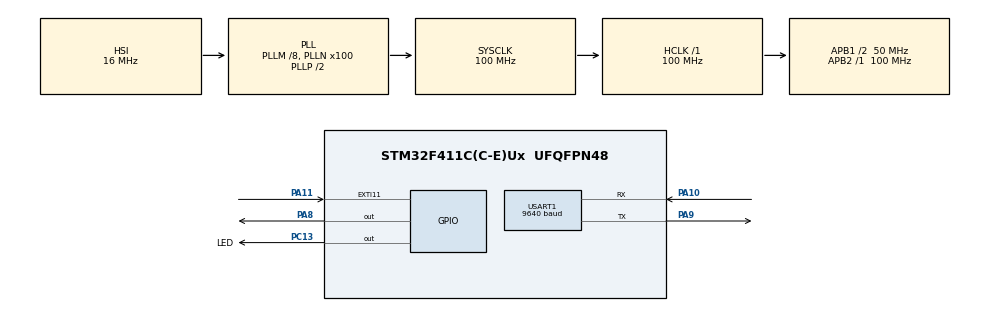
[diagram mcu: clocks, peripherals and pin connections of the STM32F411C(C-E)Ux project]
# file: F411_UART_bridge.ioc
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Dma.Request0=USART1_TX
Dma.Request1=USART1_RX
Dma.USART1_RX.1.Direction=DMA_PERIPH_TO_MEMORY
Dma.USART1_RX.1.FIFOMode=DMA_FIFOMODE_DISABLE
Dma.USART1_RX.1.Instance=DMA2_Stream2
Dma.USART1_RX.1.MemDataAlignment=DMA_MDATAALIGN_BYTE
Dma.USART1_RX.1.MemInc=DMA_MINC_ENABLE
Dma.USART1_RX.1.Mode=DMA_CIRCULAR
Dma.USART1_RX.1.PeriphDataAlignment=DMA_PDATAALIGN_BYTE
Dma.USART1_RX.1.PeriphInc=DMA_PINC_DISABLE
Dma.USART1_RX.1.Priority=DMA_PRIORITY_LOW
Dma.USART1_TX.0.Direction=DMA_MEMORY_TO_PERIPH
Dma.USART1_TX.0.FIFOMode=DMA_FIFOMODE_DISABLE
Dma.USART1_TX.0.Instance=DMA2_Stream7
Dma.USART1_TX.0.MemDataAlignment=DMA_MDATAALIGN_BYTE
Dma.USART1_TX.0.MemInc=DMA_MINC_ENABLE
Dma.USART1_TX.0.Mode=DMA_NORMAL
Dma.USART1_TX.0.PeriphDataAlignment=DMA_PDATAALIGN_BYTE
Dma.USART1_TX.0.PeriphInc=DMA_PINC_DISABLE
Dma.USART1_TX.0.Priority=DMA_PRIORITY_LOW
Mcu.Family=STM32F4
Mcu.Name=STM32F411C(C-E)Ux
Mcu.Package=UFQFPN48
NVIC.DMA2_Stream2_IRQn=true\:0\:0\:true\:false\:true\:false\:true\:true
NVIC.DMA2_Stream7_IRQn=true\:0\:0\:false\:false\:true\:false\:true\:true
NVIC.EXTI15_10_IRQn=true\:1\:0\:true\:false\:true\:true\:true\:true
NVIC.PriorityGroup=NVIC_PRIORITYGROUP_4
NVIC.USART1_IRQn=true\:0\:0\:true\:false\:true\:false\:true\:true
PA10.Mode=Asynchronous
PA10.Signal=USART1_RX
PA11.GPIO_ModeDefaultEXTI=GPIO_MODE_IT_RISING_FALLING
PA11.GPIO_PuPd=GPIO_NOPULL
PA11.Signal=GPXTI11
PA8.GPIO_ModeDefaultOutputPP=GPIO_MODE_OUTPUT_OD
PA8.GPIO_PuPd=GPIO_NOPULL
PA8.GPIO_Speed=GPIO_SPEED_FREQ_VERY_HIGH
PA8.Signal=GPIO_Output
PA9.Mode=Asynchronous
PA9.Signal=USART1_TX
PC13-ANTI_TAMP.GPIO_Label=LED
PC13-ANTI_TAMP.Signal=GPIO_Output
ProjectManager.HeapSize=0x200
ProjectManager.StackSize=0x400
ProjectManager.TargetToolchain=STM32CubeIDE
RCC.48MHZClocksFreq_Value=50000000
RCC.AHBFreq_Value=100000000
RCC.APB1CLKDivider=RCC_HCLK_DIV2
RCC.APB1Freq_Value=50000000
RCC.APB1TimFreq_Value=100000000
RCC.APB2Freq_Value=100000000
RCC.APB2TimFreq_Value=100000000
RCC.CortexFreq_Value=100000000
RCC.HCLKFreq_Value=100000000
RCC.HSE_VALUE=25000000
RCC.HSI_VALUE=16000000
RCC.LSE_VALUE=32768
RCC.PLLM=8
RCC.PLLN=100
RCC.SYSCLKFreq_VALUE=100000000
RCC.SYSCLKSource=RCC_SYSCLKSOURCE_PLLCLK
RCC.VCOOutputFreq_Value=200000000
USART1.BaudRate=9640
USART1.OverSampling=UART_OVERSAMPLING_16
USART1.StopBits=STOPBITS_1
USART1.VirtualMode=VM_ASYNC
board=custom

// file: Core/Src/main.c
/* USER CODE BEGIN Header */
/**
  ******************************************************************************
  * @file           : main.c
  * @brief          : Main program body
  ******************************************************************************
  * @attention
  *
  * Copyright (c) 2026 STMicroelectronics.
  * All rights reserved.
  *
  * This software is licensed under terms that can be found in the LICENSE file
  * in the root directory of this software component.
  * If no LICENSE file comes with this software, it is provided AS-IS.
  *
  ******************************************************************************
  */
/* USER CODE END Header */
#include "main.h"

/* USER CODE BEGIN Includes */
#include "commu_bridge.h"
/* USER CODE END Includes */

UART_HandleTypeDef huart1;
DMA_HandleTypeDef hdma_usart1_tx;
DMA_HandleTypeDef hdma_usart1_rx;

void SystemClock_Config(void);
static void MX_GPIO_Init(void);
static void MX_DMA_Init(void);
static void MX_USART1_UART_Init(void);

/* USER CODE BEGIN 0 */
uint8_t buff[] = {0x89, 0x42, 0x0, 0x2a, 0x0, 0x0, 0x14, 0xec, 0x8a};		// test only
//uint8_t buff[] = {0x89, 0x82, 0xA0, 0x0, 0xA0, 0x0, 0x91, 0x5b, 0x8A};
/* USER CODE END 0 */

int main(void)
{

  /* MCU Configuration--------------------------------------------------------*/

  /* Reset of all peripherals, Initializes the Flash interface and the Systick. */
  HAL_Init();

  /* Configure the system clock */
  SystemClock_Config();

  /* Initialize all configured peripherals */
  MX_GPIO_Init();
  MX_DMA_Init();
  MX_USART1_UART_Init();
  /* USER CODE BEGIN 2 */
  HAL_UARTEx_ReceiveToIdle_DMA(&huart1, RxBuffer, RX_SIZE);		// start circular dma-uart with idle INT

  HAL_GPIO_WritePin(LED_GPIO_Port, LED_Pin, GPIO_PIN_SET);	// OFF (init high)

  /*
  HAL_UART_Transmit_DMA(&huart1, buff, 3);	// test DMA send, success
  */
  /* USER CODE END 2 */

  /* Infinite loop */
  /* USER CODE BEGIN WHILE */
  bool has_speed_up = 0;

  while (1)
  {
    /* USER CODE END WHILE */

    /* USER CODE BEGIN 3 */
	if (has_speed_up==0 && speed_up==1){
		HAL_UART_DeInit(&huart1);
		huart1.Init.BaudRate = 227280;
		if (HAL_UART_Init(&huart1) != HAL_OK)
		{
		    Error_Handler();
		}
		HAL_UARTEx_ReceiveToIdle_DMA(&huart1, RxBuffer, RX_SIZE);	// restart dma-uart, critical

		has_speed_up = 1;
		//HAL_GPIO_WritePin(LED_GPIO_Port, LED_Pin, GPIO_PIN_RESET);		// ON
	}
	/*
    HAL_UART_Transmit(&huart1, buff, 6, 10);		// test idle, beware that use same DMA sending will jam the bus
    HAL_Delay(50);
    HAL_UART_Transmit(&huart1, buff, 6, 10);
    HAL_Delay(50);
    HAL_UART_Transmit(&huart1, buff, sizeof(buff), 10);
    HAL_Delay(50);
    */
  }
  /* USER CODE END 3 */
}

void SystemClock_Config(void)
{
  RCC_OscInitTypeDef RCC_OscInitStruct = {0};
  RCC_ClkInitTypeDef RCC_ClkInitStruct = {0};

  /** Configure the main internal regulator output voltage
  */
  __HAL_RCC_PWR_CLK_ENABLE();
  __HAL_PWR_VOLTAGESCALING_CONFIG(PWR_REGULATOR_VOLTAGE_SCALE1);

  /** Initializes the RCC Oscillators according to the specified parameters
  * in the RCC_OscInitTypeDef structure.
  */
  RCC_OscInitStruct.OscillatorType = RCC_OSCILLATORTYPE_HSI;
  RCC_OscInitStruct.HSIState = RCC_HSI_ON;
  RCC_OscInitStruct.HSICalibrationValue = RCC_HSICALIBRATION_DEFAULT;
  RCC_OscInitStruct.PLL.PLLState = RCC_PLL_ON;
  RCC_OscInitStruct.PLL.PLLSource = RCC_PLLSOURCE_HSI;
  RCC_OscInitStruct.PLL.PLLM = 8;
  RCC_OscInitStruct.PLL.PLLN = 100;
  RCC_OscInitStruct.PLL.PLLP = RCC_PLLP_DIV2;
  RCC_OscInitStruct.PLL.PLLQ = 4;
  if (HAL_RCC_OscConfig(&RCC_OscInitStruct) != HAL_OK)
  {
    Error_Handler();
  }

  /** Initializes the CPU, AHB and APB buses clocks
  */
  RCC_ClkInitStruct.ClockType = RCC_CLOCKTYPE_HCLK|RCC_CLOCKTYPE_SYSCLK
                              |RCC_CLOCKTYPE_PCLK1|RCC_CLOCKTYPE_PCLK2;
  RCC_ClkInitStruct.SYSCLKSource = RCC_SYSCLKSOURCE_PLLCLK;
  RCC_ClkInitStruct.AHBCLKDivider = RCC_SYSCLK_DIV1;
  RCC_ClkInitStruct.APB1CLKDivider = RCC_HCLK_DIV2;
  RCC_ClkInitStruct.APB2CLKDivider = RCC_HCLK_DIV1;

  if (HAL_RCC_ClockConfig(&RCC_ClkInitStruct, FLASH_LATENCY_3) != HAL_OK)
  {
    Error_Handler();
  }
}

static void MX_USART1_UART_Init(void)
{

  huart1.Instance = USART1;
  huart1.Init.BaudRate = 9640;
  huart1.Init.WordLength = UART_WORDLENGTH_8B;
  huart1.Init.StopBits = UART_STOPBITS_1;
  huart1.Init.Parity = UART_PARITY_NONE;
  huart1.Init.Mode = UART_MODE_TX_RX;
  huart1.Init.HwFlowCtl = UART_HWCONTROL_NONE;
  huart1.Init.OverSampling = UART_OVERSAMPLING_16;
  if (HAL_UART_Init(&huart1) != HAL_OK)
  {
    Error_Handler();
  }

}

static void MX_DMA_Init(void)
{

  /* DMA controller clock enable */
  __HAL_RCC_DMA2_CLK_ENABLE();

  /* DMA interrupt init */
  /* DMA2_Stream2_IRQn interrupt configuration */
  HAL_NVIC_SetPriority(DMA2_Stream2_IRQn, 0, 0);
  HAL_NVIC_EnableIRQ(DMA2_Stream2_IRQn);
  /* DMA2_Stream7_IRQn interrupt configuration */
  HAL_NVIC_SetPriority(DMA2_Stream7_IRQn, 0, 0);
  HAL_NVIC_EnableIRQ(DMA2_Stream7_IRQn);

}

static void MX_GPIO_Init(void)
{
  GPIO_InitTypeDef GPIO_InitStruct = {0};

  /* GPIO Ports Clock Enable */
  __HAL_RCC_GPIOC_CLK_ENABLE();
  __HAL_RCC_GPIOA_CLK_ENABLE();

  /*Configure GPIO pin Output Level */
  HAL_GPIO_WritePin(LED_GPIO_Port, LED_Pin, GPIO_PIN_RESET);

  /*Configure GPIO pin Output Level */
  HAL_GPIO_WritePin(GPIOA, GPIO_PIN_8, GPIO_PIN_RESET);

  /*Configure GPIO pin : LED_Pin */
  GPIO_InitStruct.Pin = LED_Pin;
  GPIO_InitStruct.Mode = GPIO_MODE_OUTPUT_PP;
  GPIO_InitStruct.Pull = GPIO_NOPULL;
  GPIO_InitStruct.Speed = GPIO_SPEED_FREQ_LOW;
  HAL_GPIO_Init(LED_GPIO_Port, &GPIO_InitStruct);

  /*Configure GPIO pin : PA8 */
  GPIO_InitStruct.Pin = GPIO_PIN_8;
  GPIO_InitStruct.Mode = GPIO_MODE_OUTPUT_OD;
  GPIO_InitStruct.Pull = GPIO_NOPULL;
  GPIO_InitStruct.Speed = GPIO_SPEED_FREQ_VERY_HIGH;
  HAL_GPIO_Init(GPIOA, &GPIO_InitStruct);

  /*Configure GPIO pin : PA11 */
  GPIO_InitStruct.Pin = GPIO_PIN_11;
  GPIO_InitStruct.Mode = GPIO_MODE_IT_RISING_FALLING;
  GPIO_InitStruct.Pull = GPIO_NOPULL;
  HAL_GPIO_Init(GPIOA, &GPIO_InitStruct);

  /* EXTI interrupt init*/
  HAL_NVIC_SetPriority(EXTI15_10_IRQn, 1, 0);
  HAL_NVIC_EnableIRQ(EXTI15_10_IRQn);

}

void Error_Handler(void)
{
  /* USER CODE BEGIN Error_Handler_Debug */
  /* User can add his own implementation to report the HAL error return state */
  __disable_irq();

  {
	  while(1){
	      HAL_GPIO_TogglePin(LED_GPIO_Port, LED_Pin);
	      HAL_Delay(200);
	  }
  }
  /* USER CODE END Error_Handler_Debug */
}
